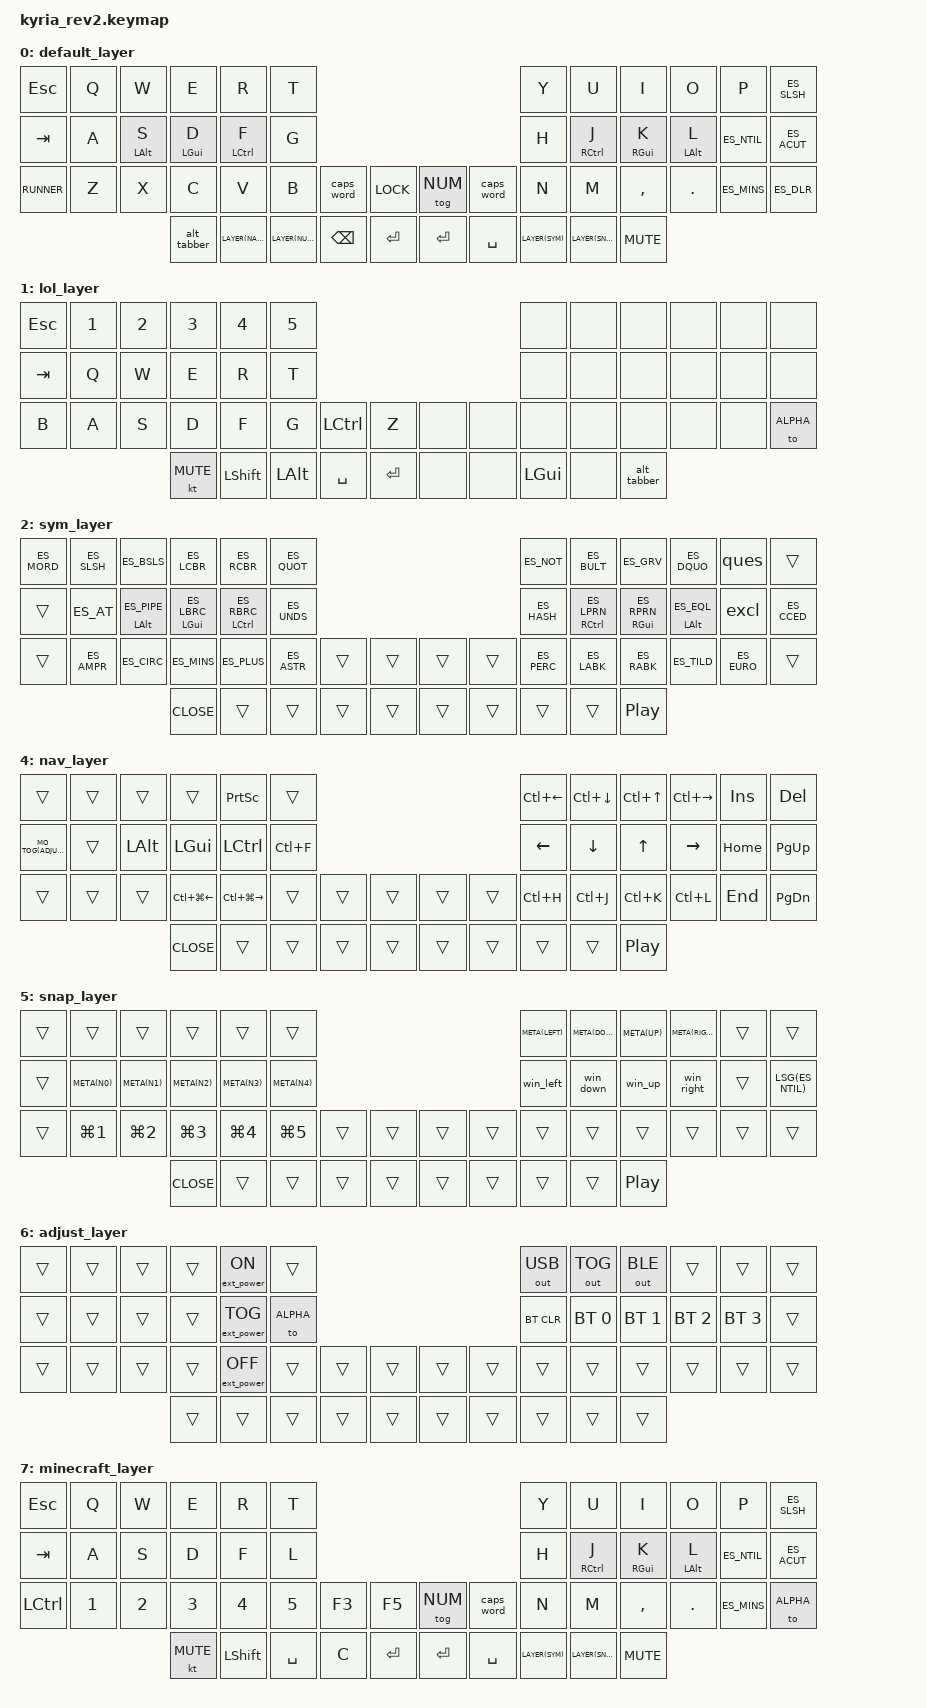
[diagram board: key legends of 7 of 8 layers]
/*
 * Copyright (c) 2020 The ZMK Contributors
 *
 * SPDX-License-Identifier: MIT
 */

#include <behaviors.dtsi>
#include <dt-bindings/zmk/keys.h>
#include <dt-bindings/zmk/bt.h>
#include <dt-bindings/zmk/outputs.h>
#include <dt-bindings/zmk/ext_power.h>
#include "keymap_spanish.h"


// Layer definitions
    #define ALPHA 0
    #define LOL 1
    #define SYM 2
    #define NUM 3
    #define NAV 4
    #define SNAP 5
    #define ADJUST 6
    #define MINECRAFT 7

// None/Trans
    #define XXXXX &none
    #define _____ &trans
// Shortcuts
    #define RUNNER LA(SPACE)
    #define LOCK LG(L)
    #define CLOSE LA(F4)
    #define MO_TOG(layer) &mo_tog layer layer
    #define MO_SL(layer) &mo_sl layer layer
    #define LAYER(layer) MO_SL(layer)
    #define META(key) LC(LA(LG(key)))
    #define LSG(key) LS(LG(key))

&caps_word {
  continue-list = <LSHFT RSHIFT ES_UNDS ES_MINS ES_PLUS BSPC ES_ACUT>;
};
// Encoder resolutions
  &left_encoder   { steps = <72>; };
  &right_encoder  { steps = <72>; };

/ {
  sensors {
    triggers-per-rotation = <36>;
  };

  macros {
    win_right: win_right {
      label = "ZM_win_right";
      compatible = "zmk,behavior-macro";
      #binding-cells = <0>;
      wait-ms = <10>;
      bindings
        = <&macro_press &kp LGUI>
        , <&macro_tap &kp RIGHT>
        , <&macro_release &kp LGUI>
        ;
    };
    win_left: win_left {
      label = "ZM_win_left";
      compatible = "zmk,behavior-macro";
      #binding-cells = <0>;
      wait-ms = <10>;
      bindings
        = <&macro_press &kp LGUI>
        , <&macro_tap &kp LEFT>
        , <&macro_release &kp LGUI>
        ;
    };
    win_up: win_up {
      label = "ZM_win_up";
      compatible = "zmk,behavior-macro";
      #binding-cells = <0>;
      wait-ms = <10>;
      bindings
        = <&macro_press &kp LGUI>
        , <&macro_tap &kp UP>
        , <&macro_release &kp LGUI>
        ;
    };
    win_down: win_down {
      label = "ZM_win_down";
      compatible = "zmk,behavior-macro";
      #binding-cells = <0>;
      wait-ms = <10>;
      bindings
        = <&macro_press &kp LGUI>
        , <&macro_tap &kp DOWN>
        , <&macro_release &kp LGUI>
        ;
    };
    alt_tabber: alt_tabber {
      label = "ZM_alt_tabber";
      compatible = "zmk,behavior-macro";
      #binding-cells = <0>;
      wait-ms = <10>;
      bindings
        = <&macro_press &kp LALT>
        , <&macro_tap &kp TAB>
        , <&macro_pause_for_release>
        , <&macro_release &kp LALT>
        ;
    };
  };

/*
 * Layout Indices
 * 00 01 02 03 04 05               06 07 08 09 10 11
 * 12 13 14 15 16 17               18 19 20 21 22 23
 * 24 25 26 27 28 29 30 31   32 33 34 35 36 37 38 39
 *          40 41 42 43 44   45 46 47 48 49         
 */

  combos {
    compatible = "zmk,combos";
    combo_esc {
      timeout-ms = <50>;
      key-positions = <19 20>;
      bindings = <&kp ESC>;
      layers = <ALPHA>;
    };
    combo_lshift {
      timeout-ms = <50>;
      key-positions = <30 43>;
      bindings = <&skq LSHFT>;
      layers = <ALPHA SYM NUM NAV>;
    };
    combo_rshift {
      timeout-ms = <50>;
      key-positions = <33 46>;
      bindings = <&skq RSHFT>;
      layers = <ALPHA SYM NUM NAV>;
    };
    combo_caps {
      timeout-ms = <50>;
      key-positions = <30 33>;
      bindings = <&kp CAPS>;
      layers = <ALPHA>;
    };
    combo_to_alpha {
      timeout-ms = <50>;
      key-positions = <24 39>;
      bindings = <&to ALPHA>;
    };
    combo_bloq_nav {
      timeout-ms = <50>;
      key-positions = <32 45>;
      bindings = <&tog NAV>;
      layers = <ALPHA NAV>;
    };
    combo_minecraft {
      timeout-ms = <50>;
      key-positions = <0 01>;
      bindings = <&to MINECRAFT>;
      layers = <ALPHA>;
    };
    combo_lol {
      timeout-ms = <50>;
      key-positions = <0 12 24>;
      bindings = <&to LOL>;
      layers = <ALPHA>;
    };
    combo_lol_to_alpha {
      timeout-ms = <50>;
      key-positions = <0 12 24>;
      bindings = <&to ALPHA>;
      layers = <LOL>;
    };
    combo_lol_ctrl {
      timeout-ms = <50>;
      key-positions = <30 43>;
      bindings = <&kp LCTRL>;
      layers = <LOL>;
    };
    combo_lol_shop {
      timeout-ms = <50>;
      key-positions = <31 44>;
      bindings = <&kp P>;
      layers = <LOL>;
    };
  };

  behaviors {
    hm: homerow_mods {
      compatible = "zmk,behavior-hold-tap";
      label = "HOMEROW_MODS";
      #binding-cells = <2>;
      tapping-term-ms = <300>;
      quick-tap-ms = <150>;
      flavor = "tap-preferred";
      bindings = <&kp>, <&kp>;
    };
    skq: sticky_key_quick_release {
      compatible = "zmk,behavior-sticky-key";
      label = "STICKY_KEY_QUICK_RELEASE";
      #binding-cells = <1>;
      bindings = <&kp>;
      release-after-ms = <1000>;
      quick-release;
    };
    mo_tog: behavior_mo_tog {
      compatible = "zmk,behavior-hold-tap";
      label = "mo_tog";
      #binding-cells = <2>;
      flavor = "hold-preferred";
      tapping-term-ms = <200>;
      bindings = <&mo>, <&tog>;
    };
    mo_sl: behavior_mo_sl {
      compatible = "zmk,behavior-hold-tap";
      label = "mo_sl";
      #binding-cells = <2>;
      flavor = "tap-unless-interrupted";
      tapping-term-ms = <200>;
      bindings = <&mo>, <&sl>;
    };
    excl: exclamation {
      compatible = "zmk,behavior-mod-morph";
      label = "EXCL_MARK";
      #binding-cells = <0>;
      bindings = <&kp ES_EXLM>, <&kp ES_IEXL>;
      mods = <(MOD_LSFT|MOD_RSFT)>;
    };
    ques: question {
      compatible = "zmk,behavior-mod-morph";
      label = "QUEST_MARK";
      #binding-cells = <0>;
      bindings = <&kp ES_QUES>, <&kp ES_IQUE>;
      mods = <(MOD_LSFT|MOD_RSFT)>;
    };
  };

	keymap {
		compatible = "zmk,keymap";

		default_layer {
    // ---------------------------------------------------------------------------------------------------------------------------
    // |  ESC  |  Q  |  W  |  E   |  R   |  T   |                                      |  Y   |  U   |  I   |  O   |  P   |  /  |
    // |  TAB  |  A  |  S  |  D   |  F   |  G   |                                      |  H   |  J   |  K   |  L   |  Ñ   |  ´  |
    // |RUNNER |  Z  |  X  |  C   |  V   |  B   |CAPS WORD| LOCK  |  |BLQ NUM|CAPS WORD|  N   |  M   |  ,   |  .   |  -   |  $  |
    //                     | ENC1 | NAV  | NUM  |    BS   | ENTER |  | ENTER |  SPACE  | SYM  | SNAP | ENC2 |
      bindings = <
        &kp ESC     &kp Q &kp W      &kp E       &kp R       &kp T                                                       &kp Y      &kp U          &kp I      &kp O      &kp P       &kp ES_SLSH
        &kp TAB     &kp A &hm LALT S &hm LGUI D  &hm LCTRL F &kp G                                                       &kp H      &hm RCTRL J    &hm RGUI K &hm LALT L &kp ES_NTIL &kp ES_ACUT
        &kp RUNNER  &kp Z &kp X      &kp C       &kp V       &kp B      &caps_word &kp LOCK        &tog NUM   &caps_word &kp N      &kp M          &kp COMMA  &kp DOT    &kp ES_MINS &kp ES_DLR
                                    &alt_tabber LAYER(NAV)  LAYER(NUM)  &kp BSPC   &kp ENTER       &kp ENTER  &kp SPACE  LAYER(SYM) LAYER(SNAP)    &kp C_MUTE
      >;

      sensor-bindings = <&inc_dec_kp LC(LG(LEFT)) LC(LG(RIGHT)) &inc_dec_kp C_VOL_DN C_VOL_UP>;
		};

		lol_layer {
    // ---------------------------------------------------------------------------------------------------------------------------
    // !!!!!!!!!!!!!!!!!!!!!!!!!!!!!!!!!!!!!!!!!!! NO ACTUALIZADO !!!!!!!!!!!!!!!!!!!!!!!!!!!!!!!!!!!!!!!!!!!!!!!!!!!!!!!!!!!!!!!!
    // |  ESC  |  1   |  2   |  3   |  4   |  5     |                                  |        |     |     |     |     |        |
    // |  TAB  |  Q   |  W   |  E   |  R   |  T     |                                  |        |     |     |     |     |        |
    // |   B   |  A   |  S   |  D   |  F   |  G     |         |         |  |     |     |        |     |     |     |     | ALPHA  |
    //                       | ENC1 | LSHFT| LCTRL  |  SPACE  |  ENTER  |  |     |     |  LGUI  |     | ENC2|
      bindings = <
        &kp ESC &kp N1 &kp N2 &kp N3 &kp N4     &kp N5                                      XXXXX    XXXXX XXXXX XXXXX XXXXX XXXXX
        &kp TAB &kp Q  &kp W  &kp E  &kp R      &kp T                                       XXXXX    XXXXX XXXXX XXXXX XXXXX XXXXX
        &kp B   &kp A  &kp S  &kp D  &kp F      &kp G    &kp LCTRL &kp Z        XXXXX XXXXX XXXXX    XXXXX XXXXX XXXXX XXXXX &to ALPHA
                       &kt C_MUTE    &kp LSHFT  &kp LALT &kp SPACE &kp ENTER    XXXXX XXXXX &kp LGUI XXXXX &alt_tabber
      >;

      sensor-bindings = <&inc_dec_kp C_VOL_DN C_VOL_UP &inc_dec_kp LS(TAB) TAB>;
		};

		sym_layer {
    // -------------------------------------------------------------------------------------------------------------------------
    // |   º   |  /  |  \  |  {   |  }   |  '   |                                    |  ¬  |  ·  |  `   |  "   |  ?¿  |     |
    // |       |  @  |  |  |  [   |  ]   |  _   |                                    |  #  |  (  |  )   |  =   |  !¡  |  ç  |
    // |       |  &  |  ^  |  -   |  +   |  *   |         |       |  |       |       |  %  |  <  |  >   |  ~   |  €   |     |
    //                     | ENC1 |      |      |         |       |  |       |       |     |     | ENC2 |
      bindings = <
        &kp ES_MORD &kp ES_SLSH &kp ES_BSLS      &kp ES_LCBR      &kp ES_RCBR       &kp ES_QUOT                              &kp ES_NOT   &kp ES_BULT       &kp ES_GRV       &kp ES_DQUO      &ques       _____
        _____       &kp ES_AT   &hm LALT ES_PIPE &hm LGUI ES_LBRC &hm LCTRL ES_RBRC &kp ES_UNDS                              &kp ES_HASH  &hm RCTRL ES_LPRN &hm RGUI ES_RPRN &hm LALT ES_EQL  &excl       &kp ES_CCED
        _____       &kp ES_AMPR &kp ES_CIRC      &kp ES_MINS      &kp ES_PLUS       &kp ES_ASTR _____ _____      _____ _____ &kp ES_PERC  &kp ES_LABK       &kp ES_RABK      &kp ES_TILD      &kp ES_EURO _____
                                                 &kp CLOSE        _____             _____       _____ _____      _____ _____ _____        _____             &kp C_PLAY_PAUSE
      >;

      sensor-bindings = <&inc_dec_kp LS(TAB) TAB &inc_dec_kp C_PREV C_NEXT>;
		};

		num_layer {
    // --------------------------------------------------------------------------------------------------------------------------
    // |       |  F1  |  F2  |   F3  |  F4   |      |                                    |  /  |  7  |  8   |  9   |  -   | BS  |
    // |       |  F5  |  F6  |   F7  |  F8   |      |                                    |  *  |  4  |  5   |  6   |  +   |  ,  |
    // |       |  F9  |  F10 |   F11 |  F12  |      |         |       |  |       |       |  =  |  1  |  2   |  3   |  .   |ENTER|
    //                       |  ENC1 |       |      |         |       |  |       |       |     |  0  | ENC2 |
      bindings = <
        _____ &kp F1 &kp F2      &kp F3      &kp F4       _____                              &kp ES_SLSH &kp N7       &kp N8      &kp N9      &kp ES_MINS &kp BSPC
        _____ &kp F5 &hm LALT F6 &hm LGUI F7 &hm LCTRL F8 _____                              &kp ES_ASTR &hm RCTRL N4 &hm RGUI N5 &hm LALT N6 &kp ES_PLUS &kp COMMA
        _____ &kp F9 &kp F10     &kp F11     &kp F12      _____ _____ _____      _____ _____ &kp ES_EQL  &kp N1       &kp N2      &kp N3      &kp DOT     &kp ENTER
                                             &kp CLOSE    _____ _____ _____      _____ _____ _____       &kp N0       &kp C_PLAY_PAUSE
      >;

      sensor-bindings = <&inc_dec_kp LS(TAB) TAB &inc_dec_kp C_PREV C_NEXT>;
		};

		nav_layer {
    // --------------------------------------------------------------------------------------------------------------------
    // |      |     |      |      |  IMPR |      |                                  | C_← | C_↓  | C_↑  | C_→ |INSERT| DEL|
    // |ADJUST|     | LALT | LGUI | LCTRL |SEARCH|                                  | ←   |   ↓  |   ↑  |  →  |INICIO|PgUP|
    // |      |     |      | D_←  |  D_→  |      |     |     |         |      |     | C_H | C_J  | C_K  | C_L | FIN  |PgDn|
    //                     |      |       |      |     |     |         |      |     |  0  |      | ENC2 |
      bindings = <
        _____          _____ _____      _____             &kp PSCRN         _____                                   &kp LC(LEFT) &kp LC(DOWN) &kp LC(UP)  &kp LC(RIGHT) &kp INSERT &kp DELETE
        MO_TOG(ADJUST) _____ &kp LALT   &kp LGUI          &kp LCTRL         &kp LC(F)                               &kp LEFT     &kp DOWN     &kp UP      &kp RIGHT     &kp HOME   &kp PG_UP
        _____          _____ _____      &kp LC(LG(LEFT))  &kp LC(LG(RIGHT)) _____     _____ _____       _____ _____ &kp LC(H)    &kp LC(J)    &kp LC(K)   &kp LC(L)     &kp END    &kp PG_DN
                                        &kp CLOSE         _____             _____     _____ _____       _____ _____ _____        _____        &kp C_PLAY_PAUSE
      >;

      sensor-bindings = <&inc_dec_kp LS(TAB) TAB &inc_dec_kp C_PREV C_NEXT>;
		};

		snap_layer {
    // --------------------------------------------------------------------------------------------------------------
    // |     |     |     |     |     |     |                                  |EXP ←|EXP ↓|EXP ↑|EXP →|      |      |
    // |     |Conf1|Conf2|Conf3|Conf4|Conf5|                                  |  ←  |  ↓  |  ↑  |  →  |      |Config|
    // |     |WIN 1|WIN 2|WIN 3|WIN 4|WIN 5|     |     |         |      |     |     |     |     |     |      |      |
    //                   |     |     |     |     |     |         |      |     |     |     | ENC2|
      bindings = <
        _____ _____        _____        _____        _____        _____                                       &kp META(LEFT) &kp META(DOWN) &kp META(UP) &kp META(RIGHT) _____ _____
        _____ &kp META(N0) &kp META(N1) &kp META(N2) &kp META(N3) &kp META(N4)                                &win_left      &win_down      &win_up      &win_right      _____ &kp LSG(ES_NTIL)
        _____ &kp LG(N1)   &kp LG(N2)   &kp LG(N3)   &kp LG(N4)   &kp LG(N5)   _____ _____        _____ _____ _____          _____          _____        _____           _____ _____
                                        &kp CLOSE    _____        _____        _____ _____        _____ _____ _____          _____          &kp C_PLAY_PAUSE
      >;

      sensor-bindings = <&inc_dec_kp LS(TAB) TAB &inc_dec_kp C_PREV C_NEXT>;
		};

		adjust_layer {
    // ---------------------------------------------------------------------------------------------------------------
    // |     |     |     |     |EP_ON |      |                                  |OUT_USB|OUT_TOG|OUT_BLE|       |       |      |
    // |     |     |     |     |EP_TOG|QWERTY|                                  |BT_CLR |BT_SEL1|BT_SEL2|BT_SEL3|BT_SEL4|      |
    // |     |     |     |     |EP_OFF|      |     |     |         |      |     |       |       |       |       |       |      |
    //                   |     |      |      |     |     |         |      |     |       |       |   ENC2|
      bindings = <
        _____ _____ _____ _____ &ext_power EP_ON  _____                                          &out OUT_USB   &out OUT_TOG &out OUT_BLE _____        _____         _____
        _____ _____ _____ _____ &ext_power EP_TOG &to ALPHA                                      &bt BT_CLR     &bt BT_SEL 0 &bt BT_SEL 1 &bt BT_SEL 2 &bt BT_SEL 3  _____
        _____ _____ _____ _____ &ext_power EP_OFF _____ _____ _____      _____ _____ _____          _____        _____        _____        _____         _____
                                     _____ _____  _____ _____ _____      _____ _____ _____          _____        _____
      >;

      sensor-bindings = <&inc_dec_kp LS(TAB) TAB &inc_dec_kp C_VOL_DN C_VOL_UP>;
		};

		minecraft_layer {
    // ---------------------------------------------------------------------------------------------------------------------------
    // !!!!!!!!!!!!!!!!!!!!!!!!!!!!!!!!!!!!!!!!!!! NO ACTUALIZADO !!!!!!!!!!!!!!!!!!!!!!!!!!!!!!!!!!!!!!!!!!!!!!!!!!!!!!!!!!!!!!!!
    // |  ESC  |  Q   |  W   |  E   |  R   |  T     |                                  |        |     |     |     |     |        |
    // | SHIFT |  A   |  S   |  D   |  F   |  L     |                                  |        |     |     |     |     |        |
    // |  CTRL |  1   |  2   |  3   |  4   |  5     |   F3    |   F5    |  |     |     |        |     |     |     |     | ALPHA  |
    //                       | ENC1 | LSHFT| SPACE  |  SPACE  |  ENTER  |  |     |     |  LGUI  |     | ENC2|
      bindings = <
        &kp ESC   &kp Q  &kp W  &kp E  &kp R      &kp T                                                  &kp Y      &kp U          &kp I      &kp O      &kp P       &kp ES_SLSH 
        &kp TAB   &kp A  &kp S  &kp D  &kp F      &kp L                                                  &kp H      &hm RCTRL J    &hm RGUI K &hm LALT L &kp ES_NTIL &kp ES_ACUT 
        &kp LCTRL &kp N1 &kp N2 &kp N3 &kp N4     &kp N5    &kp F3    &kp F5       &tog NUM   &caps_word &kp N      &kp M          &kp COMMA  &kp DOT    &kp ES_MINS &to ALPHA
                         &kt C_MUTE    &kp LSHFT  &kp SPACE &kp C &kp ENTER    &kp ENTER  &kp SPACE  LAYER(SYM) LAYER(SNAP)    &kp C_MUTE                                    
      >;

      sensor-bindings = <&inc_dec_kp C_VOL_DN C_VOL_UP &inc_dec_kp LS(TAB) TAB>;
		};
	};
};
